# HDSC_HC32F451 register map
Vendor: HDSC; Series: ARMCM4; File version: 1.0
CPU: CM4 r0p1, little endian, MPU, FPU, 4 interrupt priority bits
Registers are 32-bit, read-write, reset 0x0 unless marked. A register's access mark holds for its fields unless they carry their own. Offsets are from the block's base; [hi:lo] are bit positions; {n}, {i} and the like mark numbered series.

## KEYSCAN
Base 0x40050C00
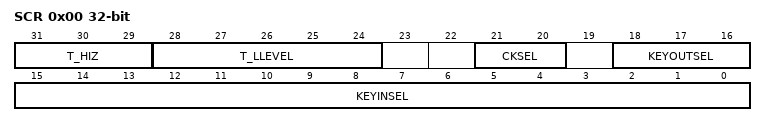
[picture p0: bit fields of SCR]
0x00 SCR
  [31:29] T_HIZ, [28:24] T_LLEVEL, [21:20] CKSEL, [18:16] KEYOUTSEL, [15:0] KEYINSEL
0x04 SER
  [0] SEN
0x08 SSR
  [2:0] INDEX

## MPU
Base 0x40050000
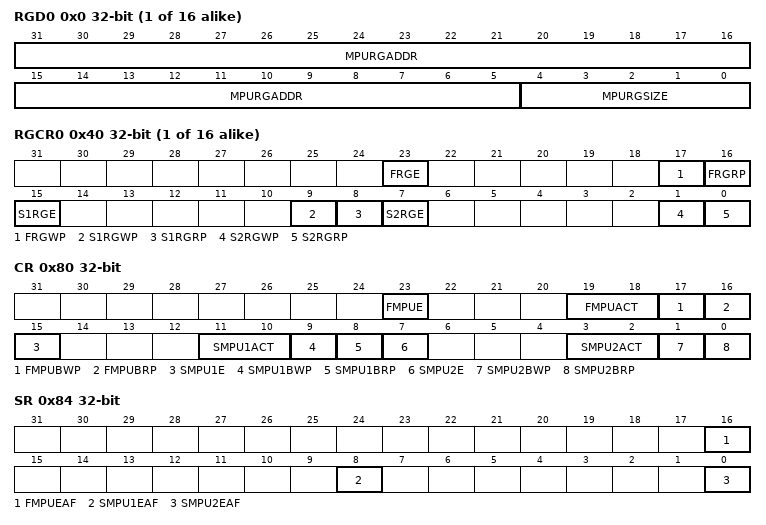
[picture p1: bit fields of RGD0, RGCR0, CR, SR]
{0x0+4i} RGD{i} (i=0..15)
  [31:5] MPURGADDR, [4:0] MPURGSIZE
{0x40+4i} RGCR{i} (i=0..15)
  [23] FRGE, [17] FRGWP, [16] FRGRP, [15] S1RGE, [9] S1RGWP, [8] S1RGRP, [7] S2RGE, [1] S2RGWP, [0] S2RGRP
0x80 CR
  [23] FMPUE, [19:18] FMPUACT, [17] FMPUBWP, [16] FMPUBRP, [15] SMPU1E, [11:10] SMPU1ACT, [9] SMPU1BWP, [8] SMPU1BRP, [7] SMPU2E, [3:2] SMPU2ACT, [1] SMPU2BWP, [0] SMPU2BRP
0x84 SR ro
  [16] FMPUEAF, [8] SMPU1EAF, [0] SMPU2EAF
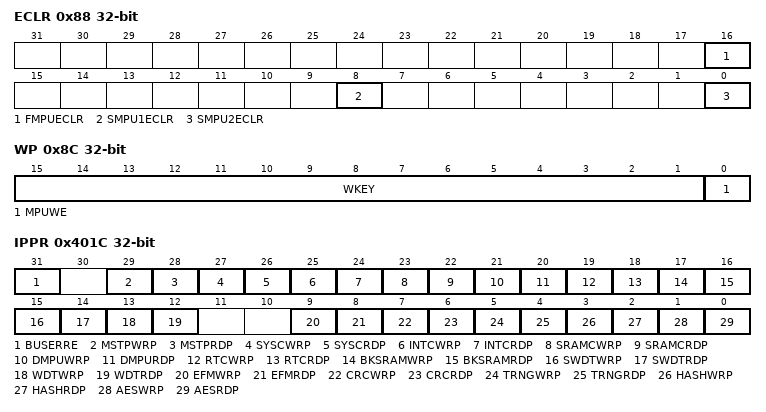
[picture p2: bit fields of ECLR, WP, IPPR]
0x88 ECLR wo
  [16] FMPUECLR, [8] SMPU1ECLR, [0] SMPU2ECLR
0x8C WP
  [15:1] WKEY wo, [0] MPUWE
0x401C IPPR
  [31] BUSERRE, [29] MSTPWRP, [28] MSTPRDP, [27] SYSCWRP, [26] SYSCRDP, [25] INTCWRP, [24] INTCRDP, [23] SRAMCWRP, [22] SRAMCRDP, [21] DMPUWRP, [20] DMPURDP, [19] RTCWRP, [18] RTCRDP, [17] BKSRAMWRP, [16] BKSRAMRDP, [15] SWDTWRP, [14] SWDTRDP, [13] WDTWRP, [12] WDTRDP, [9] EFMWRP, [8] EFMRDP, [7] CRCWRP, [6] CRCRDP, [5] TRNGWRP, [4] TRNGRDP, [3] HASHWRP, [2] HASHRDP, [1] AESWRP, [0] AESRDP

## OTS
Base 0x4004A400
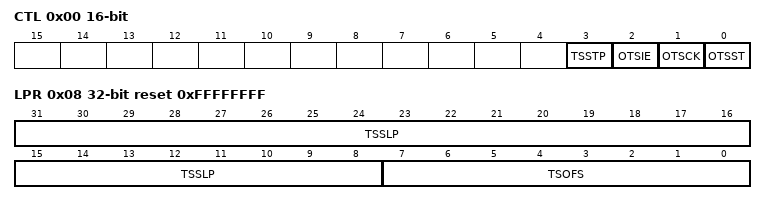
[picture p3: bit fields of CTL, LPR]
0x00 CTL 16-bit
  [3] TSSTP, [2] OTSIE, [1] OTSCK, [0] OTSST
0x02 DR1 16-bit
0x04 DR2 16-bit
0x06 ECR 16-bit
0x08 LPR ro reset 0xFFFFFFFF
  [31:8] TSSLP, [7:0] TSOFS

## PERIC
Base 0x40055400
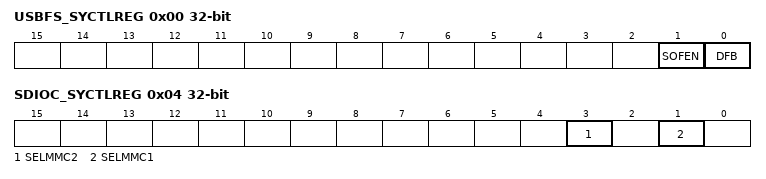
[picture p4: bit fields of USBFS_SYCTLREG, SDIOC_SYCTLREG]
0x00 USBFS_SYCTLREG
  [1] SOFEN, [0] DFB
0x04 SDIOC_SYCTLREG
  [3] SELMMC2, [1] SELMMC1

## PWC
Base 0x40048000
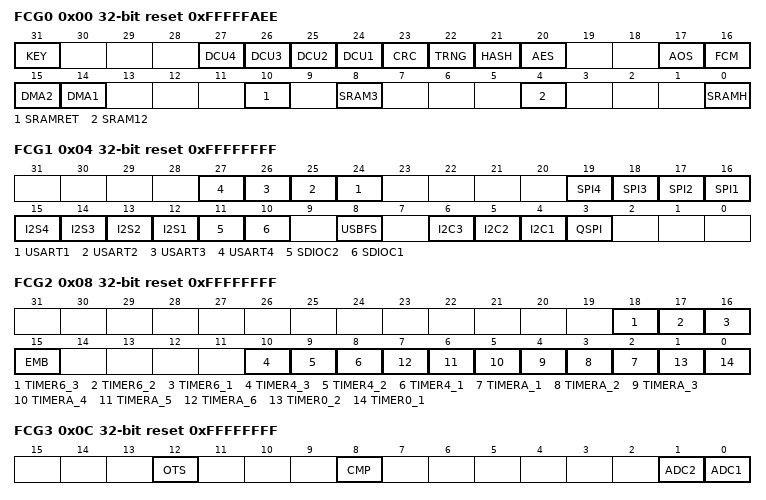
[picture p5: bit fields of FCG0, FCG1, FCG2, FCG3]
0x00 FCG0 reset 0xFFFFFAEE
  [31] KEY, [n+23] DCU{n} (n=1..4), [23] CRC, [22] TRNG, [21] HASH, [20] AES, [17] AOS, [16] FCM, [15] DMA2, [14] DMA1, [10] SRAMRET, [8] SRAM3, [4] SRAM12, [0] SRAMH
0x04 FCG1 reset 0xFFFFFFFF
  [n+23] USART{n} (n=1..4), [n+15] SPI{n} (n=1..4), [n+11] I2S{n} (n=1..4), [11] SDIOC2, [10] SDIOC1, [8] USBFS, [6] I2C3, [5] I2C2, [4] I2C1, [3] QSPI
0x08 FCG2 reset 0xFFFFFFFF
  [18] TIMER6_3, [17] TIMER6_2, [16] TIMER6_1, [15] EMB, [10] TIMER4_3, [9] TIMER4_2, [8] TIMER4_1, [n+1] TIMERA_{n} (n=1..6), [1] TIMER0_2, [0] TIMER0_1
0x0C FCG3 reset 0xFFFFFFFF
  [12] OTS, [8] CMP, [1] ADC2, [0] ADC1
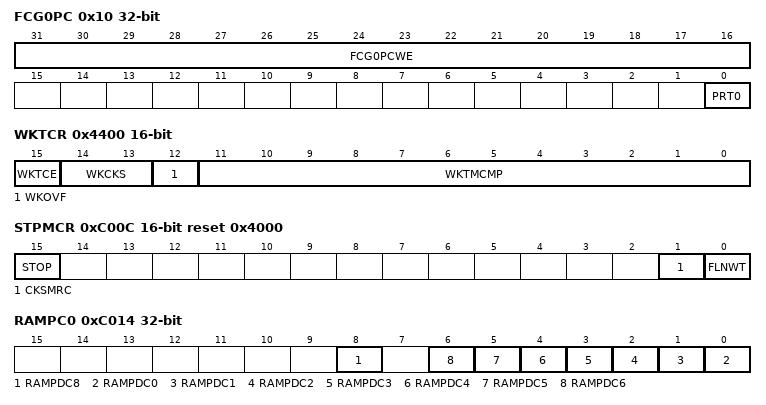
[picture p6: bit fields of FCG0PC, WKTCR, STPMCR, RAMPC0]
0x10 FCG0PC
  [31:16] FCG0PCWE wo, [0] PRT0
0x4400 WKTCR 16-bit
  [15] WKTCE, [14:13] WKCKS, [12] WKOVF, [11:0] WKTMCMP
0xC00C STPMCR 16-bit reset 0x4000
  [15] STOP, [1] CKSMRC, [0] FLNWT
0xC014 RAMPC0
  [8] RAMPDC8, [n] RAMPDC{n} (n=0..6)
0xC018 RAMOPM 16-bit reset 0x8043
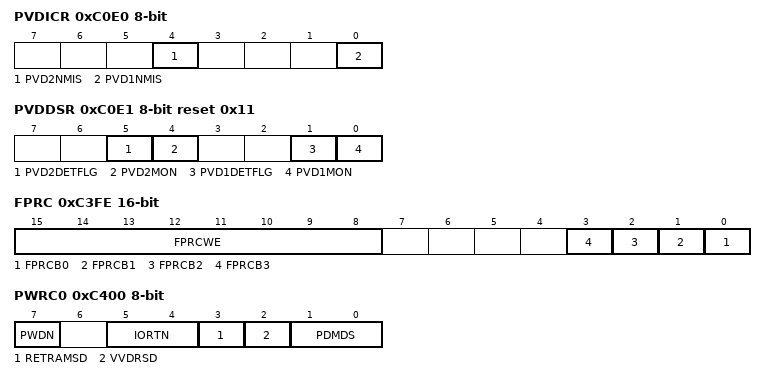
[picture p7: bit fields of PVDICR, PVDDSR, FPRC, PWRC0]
0xC0E0 PVDICR 8-bit
  [4] PVD2NMIS, [0] PVD1NMIS
0xC0E1 PVDDSR 8-bit reset 0x11
  [5] PVD2DETFLG, [4] PVD2MON, [1] PVD1DETFLG, [0] PVD1MON
0xC3FE FPRC 16-bit
  [15:8] FPRCWE, [n] FPRCB{n} (n=0..3)
0xC400 PWRC0 8-bit
  [7] PWDN, [5:4] IORTN, [3] RETRAMSD, [2] VVDRSD, [1:0] PDMDS
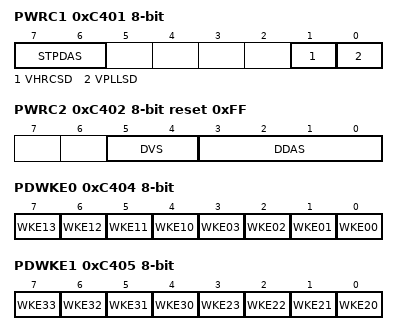
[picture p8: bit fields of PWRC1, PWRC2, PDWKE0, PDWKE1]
0xC401 PWRC1 8-bit
  [7:6] STPDAS, [1] VHRCSD, [0] VPLLSD
0xC402 PWRC2 8-bit reset 0xFF
  [5:4] DVS, [3:0] DDAS
0xC403 PWRC3 8-bit reset 0x7
  [2] PDTS
0xC404 PDWKE0 8-bit
  [n-6] WKE{n} (n=10..13), [n] WKE{n:02} (n=0..3)
0xC405 PDWKE1 8-bit
  [n-26] WKE{n} (n=30..33), [n-20] WKE{n} (n=20..23)
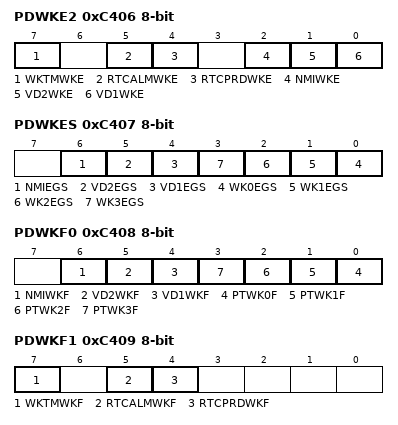
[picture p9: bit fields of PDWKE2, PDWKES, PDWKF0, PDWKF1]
0xC406 PDWKE2 8-bit
  [7] WKTMWKE, [5] RTCALMWKE, [4] RTCPRDWKE, [2] NMIWKE, [1] VD2WKE, [0] VD1WKE
0xC407 PDWKES 8-bit
  [6] NMIEGS, [5] VD2EGS, [4] VD1EGS, [n] WK{n}EGS (n=0..3)
0xC408 PDWKF0 8-bit
  [6] NMIWKF, [5] VD2WKF, [4] VD1WKF, [n] PTWK{n}F (n=0..3)
0xC409 PDWKF1 8-bit
  [7] WKTMWKF, [5] RTCALMWKF, [4] RTCPRDWKF
0xC40A PWCMR 8-bit
  [7] ADBUFE
0xC40F MDSWCR 8-bit
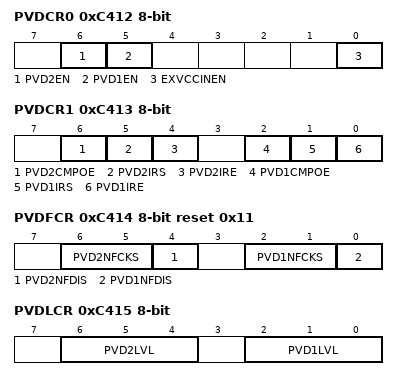
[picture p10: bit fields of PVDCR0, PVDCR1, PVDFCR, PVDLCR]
0xC412 PVDCR0 8-bit
  [6] PVD2EN, [5] PVD1EN, [0] EXVCCINEN
0xC413 PVDCR1 8-bit
  [6] PVD2CMPOE, [5] PVD2IRS, [4] PVD2IRE, [2] PVD1CMPOE, [1] PVD1IRS, [0] PVD1IRE
0xC414 PVDFCR 8-bit reset 0x11
  [6:5] PVD2NFCKS, [4] PVD2NFDIS, [2:1] PVD1NFCKS, [0] PVD1NFDIS
0xC415 PVDLCR 8-bit
  [6:4] PVD2LVL, [2:0] PVD1LVL
0xC42B XTAL32CS 8-bit reset 0x2
  [7] CSDIS
